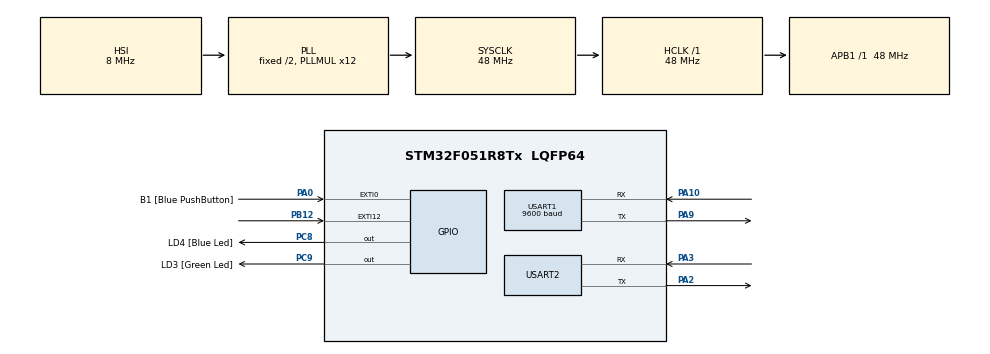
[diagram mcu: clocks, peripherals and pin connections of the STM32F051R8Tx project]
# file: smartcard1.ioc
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Dma.ADC.1.Direction=DMA_PERIPH_TO_MEMORY
Dma.ADC.1.Instance=DMA1_Channel1
Dma.ADC.1.MemDataAlignment=DMA_MDATAALIGN_HALFWORD
Dma.ADC.1.MemInc=DMA_MINC_ENABLE
Dma.ADC.1.Mode=DMA_CIRCULAR
Dma.ADC.1.PeriphDataAlignment=DMA_PDATAALIGN_HALFWORD
Dma.ADC.1.PeriphInc=DMA_PINC_DISABLE
Dma.ADC.1.Priority=DMA_PRIORITY_LOW
Dma.Request0=USART1_RX
Dma.Request1=ADC
Dma.USART1_RX.0.Direction=DMA_PERIPH_TO_MEMORY
Dma.USART1_RX.0.Instance=DMA1_Channel3
Dma.USART1_RX.0.MemDataAlignment=DMA_MDATAALIGN_BYTE
Dma.USART1_RX.0.MemInc=DMA_MINC_ENABLE
Dma.USART1_RX.0.Mode=DMA_CIRCULAR
Dma.USART1_RX.0.PeriphDataAlignment=DMA_PDATAALIGN_BYTE
Dma.USART1_RX.0.PeriphInc=DMA_PINC_DISABLE
Dma.USART1_RX.0.Priority=DMA_PRIORITY_LOW
Mcu.Family=STM32F0
Mcu.Name=STM32F051R8Tx
Mcu.Package=LQFP64
NVIC.DMA1_Channel1_IRQn=true\:0\:0\:false\:false\:true\:false
NVIC.DMA1_Channel2_3_IRQn=true\:0\:0\:false\:false\:true\:false
NVIC.EXTI4_15_IRQn=true\:0\:0\:false\:false\:true\:true
NVIC.TIM2_IRQn=true\:0\:0\:false\:false\:true\:true
NVIC.USART1_IRQn=true\:0\:0\:false\:false\:true\:true
NVIC.USART2_IRQn=true\:0\:0\:false\:false\:true\:true
PA0.GPIO_Label=B1 [Blue PushButton]
PA0.GPIO_ModeDefaultEXTI=GPIO_MODE_EVT_RISING
PA0.Signal=GPXTI0
PA10.Mode=Asynchronous
PA10.Signal=USART1_RX
PA13.GPIO_Label=SWDIO
PA13.Mode=Serial_Wire
PA13.Signal=SYS_SWDIO
PA14.GPIO_Label=SWCLK
PA14.Mode=Serial_Wire
PA14.Signal=SYS_SWCLK
PA2.Mode=Asynchronous
PA2.Signal=USART2_TX
PA3.Mode=Asynchronous
PA3.Signal=USART2_RX
PA9.Mode=Asynchronous
PA9.Signal=USART1_TX
PB12.Signal=GPXTI12
PC8.GPIO_Label=LD4 [Blue Led]
PC8.Signal=GPIO_Output
PC9.GPIO_Label=LD3 [Green Led]
PC9.Signal=GPIO_Output
ProjectManager.HeapSize=0x200
ProjectManager.StackSize=0x400
ProjectManager.TargetToolchain=SW4STM32
RCC.AHBFreq_Value=48000000
RCC.APB1Freq_Value=48000000
RCC.APB1TimFreq_Value=48000000
RCC.HCLKFreq_Value=48000000
RCC.PLLMUL=RCC_PLL_MUL12
RCC.SYSCLKFreq_VALUE=48000000
RCC.SYSCLKSource=RCC_SYSCLKSOURCE_PLLCLK
TIM2.Period=480
TIM2.Prescaler=100
USART1.BaudRate=9600
USART1.VirtualMode-Asynchronous=VM_ASYNC
USART2.VirtualMode-Asynchronous=VM_ASYNC
VP_ADC_TempSens_Input.Mode=IN-TempSens
VP_ADC_Vbat_Input.Mode=IN-Vbat
VP_TIM2_VS_ClockSourceINT.Mode=Internal
board=STM32F0DISCOVERY

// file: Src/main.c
/**
  ******************************************************************************
  * @file           : main.c
  * @brief          : Main program body
  ******************************************************************************
  ** This notice applies to any and all portions of this file
  * that are not between comment pairs USER CODE BEGIN and
  * USER CODE END. Other portions of this file, whether
  * inserted by the user or by software development tools
  * are owned by their respective copyright owners.
  *
  * COPYRIGHT(c) 2018 STMicroelectronics
  *
  * Redistribution and use in source and binary forms, with or without modification,
  * are permitted provided that the following conditions are met:
  *   1. Redistributions of source code must retain the above copyright notice,
  *      this list of conditions and the following disclaimer.
  *   2. Redistributions in binary form must reproduce the above copyright notice,
  *      this list of conditions and the following disclaimer in the documentation
  *      and/or other materials provided with the distribution.
  *   3. Neither the name of STMicroelectronics nor the names of its contributors
  *      may be used to endorse or promote products derived from this software
  *      without specific prior written permission.
  *
  * THIS SOFTWARE IS PROVIDED BY THE COPYRIGHT HOLDERS AND CONTRIBUTORS "AS IS"
  * AND ANY EXPRESS OR IMPLIED WARRANTIES, INCLUDING, BUT NOT LIMITED TO, THE
  * IMPLIED WARRANTIES OF MERCHANTABILITY AND FITNESS FOR A PARTICULAR PURPOSE ARE
  * DISCLAIMED. IN NO EVENT SHALL THE COPYRIGHT HOLDER OR CONTRIBUTORS BE LIABLE
  * FOR ANY DIRECT, INDIRECT, INCIDENTAL, SPECIAL, EXEMPLARY, OR CONSEQUENTIAL
  * DAMAGES (INCLUDING, BUT NOT LIMITED TO, PROCUREMENT OF SUBSTITUTE GOODS OR
  * SERVICES; LOSS OF USE, DATA, OR PROFITS; OR BUSINESS INTERRUPTION) HOWEVER
  * CAUSED AND ON ANY THEORY OF LIABILITY, WHETHER IN CONTRACT, STRICT LIABILITY,
  * OR TORT (INCLUDING NEGLIGENCE OR OTHERWISE) ARISING IN ANY WAY OUT OF THE USE
  * OF THIS SOFTWARE, EVEN IF ADVISED OF THE POSSIBILITY OF SUCH DAMAGE.
  *
  ******************************************************************************
  */
#include "main.h"
#include "stm32f0xx_hal.h"

ADC_HandleTypeDef hadc;
DMA_HandleTypeDef hdma_adc;

TIM_HandleTypeDef htim2;

UART_HandleTypeDef huart1;
UART_HandleTypeDef huart2;
DMA_HandleTypeDef hdma_usart1_rx;

/* USER CODE BEGIN PV */
/* Private variables ---------------------------------------------------------*/

/* USER CODE END PV */

void SystemClock_Config(void);
static void MX_GPIO_Init(void);
static void MX_DMA_Init(void);
static void MX_USART1_UART_Init(void);
static void MX_USART2_UART_Init(void);
static void MX_TIM2_Init(void);
static void MX_ADC_Init(void);
static uint8_t datatest[16];
/* USER CODE BEGIN PFP */
/* Private function prototypes -----------------------------------------------*/

/* USER CODE END PFP */

int main(void)
{

  /* MCU Configuration----------------------------------------------------------*/

  /* Reset of all peripherals, Initializes the Flash interface and the Systick. */
  HAL_Init();

  /* Configure the system clock */
  SystemClock_Config();

  /* Initialize all configured peripherals */
  MX_GPIO_Init();
  MX_DMA_Init();
  MX_USART1_UART_Init();
  MX_USART2_UART_Init();
  MX_TIM2_Init();
  MX_ADC_Init();
  /* USER CODE BEGIN 2 */
  HAL_UART_Receive_DMA(&huart1,datatest,16);
  /* USER CODE END 2 */

  /* Infinite loop */
  while (1)
  {
	  HAL_GPIO_TogglePin(GPIOC,GPIO_PIN_8);
	  HAL_Delay(100);
  }

}

void SystemClock_Config(void)
{

  RCC_OscInitTypeDef RCC_OscInitStruct;
  RCC_ClkInitTypeDef RCC_ClkInitStruct;
  RCC_PeriphCLKInitTypeDef PeriphClkInit;

    /**Initializes the CPU, AHB and APB busses clocks
    */
  RCC_OscInitStruct.OscillatorType = RCC_OSCILLATORTYPE_HSI|RCC_OSCILLATORTYPE_HSI14;
  RCC_OscInitStruct.HSIState = RCC_HSI_ON;
  RCC_OscInitStruct.HSI14State = RCC_HSI14_ON;
  RCC_OscInitStruct.HSICalibrationValue = 16;
  RCC_OscInitStruct.HSI14CalibrationValue = 16;
  RCC_OscInitStruct.PLL.PLLState = RCC_PLL_ON;
  RCC_OscInitStruct.PLL.PLLSource = RCC_PLLSOURCE_HSI;
  RCC_OscInitStruct.PLL.PLLMUL = RCC_PLL_MUL12;
  RCC_OscInitStruct.PLL.PREDIV = RCC_PREDIV_DIV1;
  if (HAL_RCC_OscConfig(&RCC_OscInitStruct) != HAL_OK)
  {
    _Error_Handler(__FILE__, __LINE__);
  }

    /**Initializes the CPU, AHB and APB busses clocks
    */
  RCC_ClkInitStruct.ClockType = RCC_CLOCKTYPE_HCLK|RCC_CLOCKTYPE_SYSCLK
                              |RCC_CLOCKTYPE_PCLK1;
  RCC_ClkInitStruct.SYSCLKSource = RCC_SYSCLKSOURCE_PLLCLK;
  RCC_ClkInitStruct.AHBCLKDivider = RCC_SYSCLK_DIV1;
  RCC_ClkInitStruct.APB1CLKDivider = RCC_HCLK_DIV1;

  if (HAL_RCC_ClockConfig(&RCC_ClkInitStruct, FLASH_LATENCY_1) != HAL_OK)
  {
    _Error_Handler(__FILE__, __LINE__);
  }

  PeriphClkInit.PeriphClockSelection = RCC_PERIPHCLK_USART1;
  PeriphClkInit.Usart1ClockSelection = RCC_USART1CLKSOURCE_PCLK1;
  if (HAL_RCCEx_PeriphCLKConfig(&PeriphClkInit) != HAL_OK)
  {
    _Error_Handler(__FILE__, __LINE__);
  }

    /**Configure the Systick interrupt time
    */
  HAL_SYSTICK_Config(HAL_RCC_GetHCLKFreq()/1000);

    /**Configure the Systick
    */
  HAL_SYSTICK_CLKSourceConfig(SYSTICK_CLKSOURCE_HCLK);

  /* SysTick_IRQn interrupt configuration */
  HAL_NVIC_SetPriority(SysTick_IRQn, 0, 0);
}

/* ADC init function */
static void MX_ADC_Init(void)
{

  ADC_ChannelConfTypeDef sConfig;

    /**Configure the global features of the ADC (Clock, Resolution, Data Alignment and number of conversion)
    */
  hadc.Instance = ADC1;
  hadc.Init.ClockPrescaler = ADC_CLOCK_ASYNC_DIV1;
  hadc.Init.Resolution = ADC_RESOLUTION_12B;
  hadc.Init.DataAlign = ADC_DATAALIGN_RIGHT;
  hadc.Init.ScanConvMode = ADC_SCAN_DIRECTION_FORWARD;
  hadc.Init.EOCSelection = ADC_EOC_SINGLE_CONV;
  hadc.Init.LowPowerAutoWait = DISABLE;
  hadc.Init.LowPowerAutoPowerOff = DISABLE;
  hadc.Init.ContinuousConvMode = DISABLE;
  hadc.Init.DiscontinuousConvMode = DISABLE;
  hadc.Init.ExternalTrigConv = ADC_SOFTWARE_START;
  hadc.Init.ExternalTrigConvEdge = ADC_EXTERNALTRIGCONVEDGE_NONE;
  hadc.Init.DMAContinuousRequests = DISABLE;
  hadc.Init.Overrun = ADC_OVR_DATA_PRESERVED;
  if (HAL_ADC_Init(&hadc) != HAL_OK)
  {
    _Error_Handler(__FILE__, __LINE__);
  }

    /**Configure for the selected ADC regular channel to be converted.
    */
  sConfig.Channel = ADC_CHANNEL_TEMPSENSOR;
  sConfig.Rank = ADC_RANK_CHANNEL_NUMBER;
  sConfig.SamplingTime = ADC_SAMPLETIME_1CYCLE_5;
  if (HAL_ADC_ConfigChannel(&hadc, &sConfig) != HAL_OK)
  {
    _Error_Handler(__FILE__, __LINE__);
  }

    /**Configure for the selected ADC regular channel to be converted.
    */
  sConfig.Channel = ADC_CHANNEL_VBAT;
  if (HAL_ADC_ConfigChannel(&hadc, &sConfig) != HAL_OK)
  {
    _Error_Handler(__FILE__, __LINE__);
  }

}

/* TIM2 init function */
static void MX_TIM2_Init(void)
{

  TIM_ClockConfigTypeDef sClockSourceConfig;
  TIM_MasterConfigTypeDef sMasterConfig;

  htim2.Instance = TIM2;
  htim2.Init.Prescaler = 100;
  htim2.Init.CounterMode = TIM_COUNTERMODE_UP;
  htim2.Init.Period = 480;
  htim2.Init.ClockDivision = TIM_CLOCKDIVISION_DIV1;
  htim2.Init.AutoReloadPreload = TIM_AUTORELOAD_PRELOAD_DISABLE;
  if (HAL_TIM_Base_Init(&htim2) != HAL_OK)
  {
    _Error_Handler(__FILE__, __LINE__);
  }

  sClockSourceConfig.ClockSource = TIM_CLOCKSOURCE_INTERNAL;
  if (HAL_TIM_ConfigClockSource(&htim2, &sClockSourceConfig) != HAL_OK)
  {
    _Error_Handler(__FILE__, __LINE__);
  }

  sMasterConfig.MasterOutputTrigger = TIM_TRGO_RESET;
  sMasterConfig.MasterSlaveMode = TIM_MASTERSLAVEMODE_DISABLE;
  if (HAL_TIMEx_MasterConfigSynchronization(&htim2, &sMasterConfig) != HAL_OK)
  {
    _Error_Handler(__FILE__, __LINE__);
  }

}

/* USART1 init function */
static void MX_USART1_UART_Init(void)
{

  huart1.Instance = USART1;
  huart1.Init.BaudRate = 9600;
  huart1.Init.WordLength = UART_WORDLENGTH_8B;
  huart1.Init.StopBits = UART_STOPBITS_1;
  huart1.Init.Parity = UART_PARITY_NONE;
  huart1.Init.Mode = UART_MODE_TX_RX;
  huart1.Init.HwFlowCtl = UART_HWCONTROL_NONE;
  huart1.Init.OverSampling = UART_OVERSAMPLING_16;
  huart1.Init.OneBitSampling = UART_ONE_BIT_SAMPLE_DISABLE;
  huart1.AdvancedInit.AdvFeatureInit = UART_ADVFEATURE_NO_INIT;
  if (HAL_UART_Init(&huart1) != HAL_OK)
  {
    _Error_Handler(__FILE__, __LINE__);
  }

}

/* USART2 init function */
static void MX_USART2_UART_Init(void)
{

  huart2.Instance = USART2;
  huart2.Init.BaudRate = 38400;
  huart2.Init.WordLength = UART_WORDLENGTH_8B;
  huart2.Init.StopBits = UART_STOPBITS_1;
  huart2.Init.Parity = UART_PARITY_NONE;
  huart2.Init.Mode = UART_MODE_TX_RX;
  huart2.Init.HwFlowCtl = UART_HWCONTROL_NONE;
  huart2.Init.OverSampling = UART_OVERSAMPLING_16;
  huart2.Init.OneBitSampling = UART_ONE_BIT_SAMPLE_DISABLE;
  huart2.AdvancedInit.AdvFeatureInit = UART_ADVFEATURE_NO_INIT;
  if (HAL_UART_Init(&huart2) != HAL_OK)
  {
    _Error_Handler(__FILE__, __LINE__);
  }

}

static void MX_DMA_Init(void)
{
  /* DMA controller clock enable */
  __HAL_RCC_DMA1_CLK_ENABLE();

  /* DMA interrupt init */
  /* DMA1_Channel1_IRQn interrupt configuration */
  HAL_NVIC_SetPriority(DMA1_Channel1_IRQn, 0, 0);
  HAL_NVIC_EnableIRQ(DMA1_Channel1_IRQn);
  /* DMA1_Channel2_3_IRQn interrupt configuration */
  HAL_NVIC_SetPriority(DMA1_Channel2_3_IRQn, 0, 0);
  HAL_NVIC_EnableIRQ(DMA1_Channel2_3_IRQn);

}

/** Configure pins as
        * Analog
        * Input
        * Output
        * EVENT_OUT
        * EXTI
*/
static void MX_GPIO_Init(void)
{

  GPIO_InitTypeDef GPIO_InitStruct;

  /* GPIO Ports Clock Enable */
  __HAL_RCC_GPIOA_CLK_ENABLE();
  __HAL_RCC_GPIOB_CLK_ENABLE();
  __HAL_RCC_GPIOC_CLK_ENABLE();

  /*Configure GPIO pin Output Level */
  HAL_GPIO_WritePin(GPIOC, LD4_Pin|LD3_Pin, GPIO_PIN_RESET);

  /*Configure GPIO pin : B1_Pin */
  GPIO_InitStruct.Pin = B1_Pin;
  GPIO_InitStruct.Mode = GPIO_MODE_EVT_RISING;
  GPIO_InitStruct.Pull = GPIO_NOPULL;
  HAL_GPIO_Init(B1_GPIO_Port, &GPIO_InitStruct);

  /*Configure GPIO pin : PB12 */
  GPIO_InitStruct.Pin = GPIO_PIN_12;
  GPIO_InitStruct.Mode = GPIO_MODE_IT_RISING;
  GPIO_InitStruct.Pull = GPIO_NOPULL;
  HAL_GPIO_Init(GPIOB, &GPIO_InitStruct);

  /*Configure GPIO pins : LD4_Pin LD3_Pin */
  GPIO_InitStruct.Pin = LD4_Pin|LD3_Pin;
  GPIO_InitStruct.Mode = GPIO_MODE_OUTPUT_PP;
  GPIO_InitStruct.Pull = GPIO_NOPULL;
  GPIO_InitStruct.Speed = GPIO_SPEED_FREQ_LOW;
  HAL_GPIO_Init(GPIOC, &GPIO_InitStruct);

  /* EXTI interrupt init*/
  HAL_NVIC_SetPriority(EXTI4_15_IRQn, 0, 0);
  HAL_NVIC_EnableIRQ(EXTI4_15_IRQn);

}

void _Error_Handler(char *file, int line)
{
  while(1)
  {
  }
}

/************************ (C) COPYRIGHT STMicroelectronics *****END OF FILE****/
